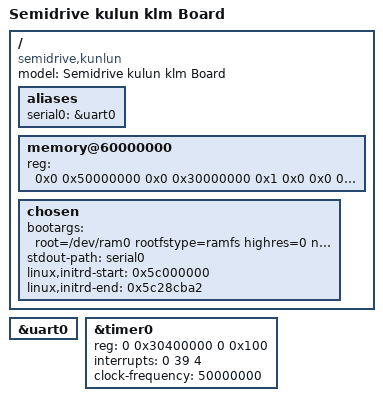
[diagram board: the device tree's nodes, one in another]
/*
 * Spreadtrum SC9836 openphone board DTS file
 *
 * Copyright (C) 2014, Spreadtrum Communications Inc.
 *
 * This file is licensed under a dual GPLv2 or X11 license.
 */

/dts-v1/;

#include "klm.dtsi"

/ {
	model = "Semidrive kulun klm Board";

	compatible = "semidrive,kunlun";

	aliases {
		serial0 = &uart0;
	};

	memory@60000000 {
		device_type = "memory";
		reg = <0x0 0x50000000 0x0 0x30000000 0x1 0x0 0x0 0x40000000>;
	};

	chosen {
		bootargs = "root=/dev/ram0 rootfstype=ramfs highres=0 nohlt earlycon nosmp loglevel=11 console=ttyS0,115200n8 rdinit=/linuxrc";
		stdout-path = "serial0";
		linux,initrd-start = <0x5c000000>;
		linux,initrd-end   = <0x5c28cba2>;
	};
};

&uart0 {
	status = "okay";
};

&timer0 {
	reg = <0 0x30400000 0 0x100>;
	interrupts = <0 39 4>;
	clock-frequency = <50000000>;
	status = "okay";
};

